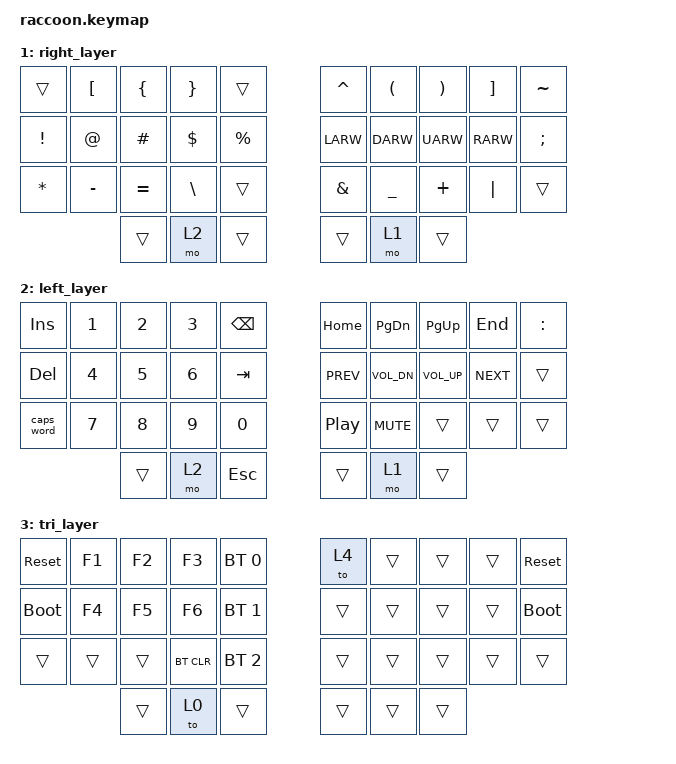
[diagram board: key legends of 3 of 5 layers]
// Copyright (c) 2022 The ZMK Contributors
// SPDX-License-Identifier: MIT

#include <behaviors.dtsi>
#include <dt-bindings/zmk/keys.h>
#include <dt-bindings/zmk/bt.h>

// Home row mods macro
#define HRML(k1,k2,k3,k4) &ht LSHFT k1  &ht LALT k2  &ht LCTRL k3  &ht LGUI k4
#define HRMR(k1,k2,k3,k4) &ht RGUI k1  &ht RCTRL k2  &ht RALT k3  &ht RSHFT k4

/ {
    behaviors {
        ht: hold_tap {
            compatible = "zmk,behavior-hold-tap";
            #binding-cells = <2>;
            flavor = "tap-preferred";
            tapping-term-ms = <220>;
            quick-tap-ms = <150>;
            require-prior-idle-ms = <100>;
            bindings = <&kp>, <&kp>;
        };
    };

    conditional_layers {
        compatible = "zmk,conditional-layers";
        tri_layer {
            if-layers = <1 2>;
            then-layer = <3>;
        };
    };

    keymap {
        compatible = "zmk,keymap";
        default_layer {
            bindings = <
        //╭──────────┬──────────┬──────────┬──────────┬──────────╮   ╭──────────┬──────────┬──────────┬──────────┬──────────╮
        //│  Q       │  W       │  E       │  R       │  T       │   │  Y       │  U       │  I       │  O       │  P       │
            &ht ESC Q	&kp W      &kp E      &kp R      &kp T          &kp Y      &kp U      &kp I      &kp O      &kp P
        //├──────────┼──────────┼──────────┼──────────┼──────────┤   ├──────────┼──────────┼──────────┼──────────┼──────────┤
        //│  A       │  S       │  D       │  F       │  G       │   │  H       │  J       │  K       │  L       │ ' "      │
            HRML(A,        S,         D,         F)     &kp G          &kp H      &kp J      &kp K     &kp L     &kp SQT
        //├──────────┼──────────┼──────────┼──────────┼──────────┤   ├──────────┼──────────┼──────────┼──────────┼──────────┤
        //│  Z       │  X       │  C       │  V       │  B       │   │  N       │  M       │ , <      │ . >      │ / ?      │
            &kp Z      &kp X      &kp C      &kp V      &kp B          &kp N      HRMR(M,    COMMA,     DOT,       FSLH)
        //╰──────────┴──────────┼──────────┼──────────┼──────────┤   ├──────────┼──────────┼──────────┼──────────┴──────────╯
                                 &key_repeat  &mo 2      &kp SPACE      &kp ENTER  &mo 1      &kp LGUI
        //                      ╰──────────┴──────────┴──────────╯   ╰──────────┴──────────┴──────────╯
            >;
        };
		
        right_layer {
            bindings = <
        //╭──────────┬──────────┬──────────┬──────────┬──────────╮   ╭──────────┬──────────┬──────────┬──────────┬──────────╮
        //│          │  [       │  {       │  }       │          │   │  ^       │  (       │  )       │  ]       │  ~       │
            &trans     &kp LBKT   &kp LBRC   &kp RBRC   &trans         &kp CARET  &kp LPAR   &kp RPAR   &kp RBKT   &kp TILDE
        //├──────────┼──────────┼──────────┼──────────┼──────────┤   ├──────────┼──────────┼──────────┼──────────┼──────────┤
        //│  !       │  @       │  #       │  $       │  %       │   │ LEFT     │ DOWN     │ UP       │ RIGHT    │  `       │
            &kp EXCL   &kp AT     &kp HASH   &kp DLLR   &kp PRCNT       &kp LARW   &kp DARW   &kp UARW   &kp RARW   &kp SEMI
        //├──────────┼──────────┼──────────┼──────────┼──────────┤   ├──────────┼──────────┼──────────┼──────────┼──────────┤
        //│  *       │  -       │  =       │  \       │          │   │  &       │  _       │  +       │  │       │          │
            &kp ASTRK  &kp MINUS  &kp EQUAL  &kp BSLH 	&trans			&kp AMPS   &kp UNDER  &kp PLUS   &kp PIPE   &trans
        //╰──────────┴──────────┼──────────┼──────────┼──────────┤   ├──────────┼──────────┼──────────┼──────────┴──────────╯
                                  &trans     &mo 2		&trans         &trans     &mo 1       &trans
        //                      ╰──────────┴──────────┴──────────╯   ╰──────────┴──────────┴──────────╯
            >;
        };
		
        left_layer {
            bindings = <
        //╭──────────┬──────────┬──────────┬──────────┬──────────╮   ╭──────────┬──────────┬──────────┬──────────┬──────────╮
        //│ INSERT   │  1       │  2       │  3       │ Backspace│   │ HOME     │ PAGE DN  │ PAGE UP  │ END      │  :       │
            &kp INS    &kp N1     &kp N2     &kp N3     &kp BSPC       &kp HOME   &kp PG_DN  &kp PG_UP  &kp END    &kp COLON
        //├──────────┼──────────┼──────────┼──────────┼──────────┤   ├──────────┼──────────┼──────────┼──────────┼──────────┤
        //│ DELETE   │  4       │  5       │  6       │          │   │          │          │          │          │          │
            &kp DEL    &kp N4     &kp N5     &kp N6     &kp TAB   	   &kp C_PREV &kp C_VOL_DN &kp C_VOL_UP &kp C_NEXT &trans
        //├──────────┼──────────┼──────────┼──────────┼──────────┤   ├──────────┼──────────┼──────────┼──────────┼──────────┤
        //│ CAPS     │  7       │  8       │  9       │  0       │   │          │          │          │          │          │
           &caps_word  &kp N7     &kp N8     &kp N9     &kp N0         &kp C_PP	  &kp C_MUTE &trans     &trans     &trans
        //╰──────────┴──────────┼──────────┼──────────┼──────────┤   ├──────────┼──────────┼──────────┼──────────┴──────────╯
                                  &trans     &mo 2		&kp ESC        &trans     &mo 1      &trans
        //                      ╰──────────┴──────────┴──────────╯   ╰──────────┴──────────┴──────────╯
            >;
        };

        tri_layer {
            bindings = <
        //╭──────────┬──────────┬──────────┬──────────┬──────────╮   ╭──────────┬──────────┬──────────┬──────────┬──────────╮
        //│ RESET    │          │          │          │PROFILE 0 │   │  LEAGUE  │          │          │          │  RESET   │
           &sys_reset  &kp F1     &kp F2     &kp F3    &bt BT_SEL 0    &to 4      &trans     &trans     &trans    &sys_reset
        //├──────────┼──────────┼──────────┼──────────┼──────────┤   ├──────────┼──────────┼──────────┼──────────┼──────────┤
        //│BOOTLOADER│          │          │          │PROFILE 1 │   │          │          │          │          │BOOTLOADER│
          &bootloader  &kp F4     &kp F5     &kp F6    &bt BT_SEL 1    &trans     &trans     &trans     &trans    &bootloader
        //├──────────┼──────────┼──────────┼──────────┼──────────┤   ├──────────┼──────────┼──────────┼──────────┼──────────┤
        //│          │          │          │ CLEAR BT │PROFILE 2 │   │          │          │          │          │          │
            &trans     &trans     &trans    &bt BT_CLR &bt BT_SEL 2    &trans     &trans     &trans     &trans     &trans
        //╰──────────┴──────────┼──────────┼──────────┼──────────┤   ├──────────┼──────────┼──────────┼──────────┴──────────╯
                                  &trans     &to 0     &trans         &trans     &trans     &trans
        //                      ╰──────────┴──────────┴──────────╯   ╰──────────┴──────────┴──────────╯
            >;
        };
		league_layer {
            bindings = <
        //╭──────────┬──────────┬──────────┬──────────┬──────────╮   ╭──────────┬──────────┬──────────┬──────────┬──────────╮
        //│  Q       │  W       │  E       │  R       │  T       │   │  Y       │  U       │  I       │  O       │  P       │
            &kp Q		&kp W      &kp E      &kp R      &kp T          &kp Y      &kp U      &kp I      &kp O      &kp P
        //├──────────┼──────────┼──────────┼──────────┼──────────┤   ├──────────┼──────────┼──────────┼──────────┼──────────┤
        //│  A       │  S       │  D       │  F       │  G       │   │  H       │  J       │  K       │  L       │ ' "      │
            HRML(A,        S,         D,         F)     &kp G          &kp H      HRMR(J,        K,         L,        SQT)
        //├──────────┼──────────┼──────────┼──────────┼──────────┤   ├──────────┼──────────┼──────────┼──────────┼──────────┤
        //│  Z       │  X       │  C       │  V       │  B       │   │  N       │  M       │ , <      │ . >      │ / ?      │
            &kp Z      &kp X      &kp C      &kp V      &kp B          &kp N      &kp M      &kp COMMA  &kp DOT    &kp FSLH
        //╰──────────┴──────────┼──────────┼──────────┼──────────┤   ├──────────┼──────────┼──────────┼──────────┴──────────╯
                                 &key_repeat  &mo 2      &kp SPACE      &kp ENTER  &to 0      &kp LC(LS(LALT)) 
        //                      ╰──────────┴──────────┴──────────╯   ╰──────────┴──────────┴──────────╯
            >;
        };
    };
};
